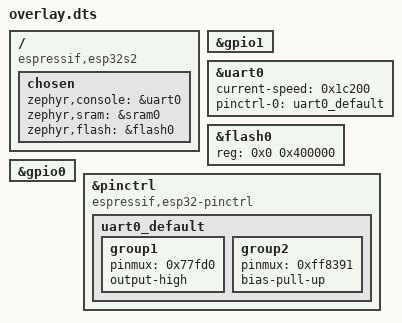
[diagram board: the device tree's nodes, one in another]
/ {
	compatible = "espressif,esp32s2";
	chosen {
		zephyr,console = &uart0;
		zephyr,sram = &sram0;
		zephyr,flash = &flash0;
	};
};
&gpio1{
	status = "okay";
};
&uart0{
	status = "okay";
	current-speed = < 0x1c200 >;
	pinctrl-0 = < &uart0_default >;
	pinctrl-names = "default";
};
&flash0{
	reg = < 0x0 0x400000 >;
	status = "okay";
};
&gpio0{
	status = "okay";
};
&pinctrl{
	compatible = "espressif,esp32-pinctrl";
	status = "okay";
	uart0_default: uart0_default {
		group1 {
			pinmux = < 0x77fd0 >;
			output-high;
		};
		group2 {
			pinmux = < 0xff8391 >;
			bias-pull-up;
		};
	};
};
